AUTOSAR XML (schema 4-2-1)
package /VehicleProject
  system System
package /TP
  can tp config CAN00_CAN: communication-cluster=CAN00, can-tp-ecu{cycle-time-main-function=0.005, ecu-instance=MyECU}
    can tp channel TPCH: channel-id=0, channel-mode=FULL-DUPLEX-MODE
    tp-connections:
      addressing-format=STANDARD, can-tp-channel=TPCH, data-pdu=msg_diag_RequestGlobal_Tp_oCAN00, receiver=TN_MyECU, ta-type=FUNCTIONAL, tp-sdu=msg_diag_RequestGlobal_oCAN00, transmitter=TN_Tester
      addressing-format=STANDARD, can-tp-channel=TPCH, data-pdu=msg_diag_Response_MyECU_Tp_oCAN00, flow-control-pdu=msg_diag_Request_MyECU_Tp_oCAN00, receiver=TN_Tester, ta-type=PHYSICAL, tp-sdu=msg_diag_Response_MyECU_oCAN00, transmitter=TN_MyECU
      addressing-format=STANDARD, can-tp-channel=TPCH, data-pdu=msg_diag_Request_MyECU_Tp_oCAN00, flow-control-pdu=msg_diag_Response_MyECU_Tp_oCAN00, receiver=TN_MyECU, ta-type=PHYSICAL, tp-sdu=msg_diag_Request_MyECU_oCAN00, transmitter=TN_Tester
    can tp node TN_MyECU: connector=CN_CAN00
    can tp node TN_Tester
package /Cluster
  can cluster CAN00: protocol-name=CAN
    can physical channel CHNL: comm-connectors=CN_CAN00
      frame msg_diag_Request_MyECU_oCAN00: id 0x610, to MyECU, frame-length=8, can-addressing-mode=STANDARD
        n pdu msg_diag_Request_MyECU_Tp_oCAN00: length=8
      frame msg_diag_RequestGlobal_oCAN00: id 0x614, to MyECU, frame-length=8, can-addressing-mode=STANDARD
        n pdu msg_diag_RequestGlobal_Tp_oCAN00: length=8
      frame msg_diag_Response_MyECU_oCAN00: id 0x612, from MyECU, frame-length=8, can-addressing-mode=STANDARD
        n pdu msg_diag_Response_MyECU_Tp_oCAN00: length=8
      frame msg_nm_MyECU_oCAN00: id 0x400, from MyECU, frame-length=8, can-addressing-mode=STANDARD
        nm pdu msg_nm_MyECU_oCAN00: length=8, unused-bit-pattern=0
      frame msg_nm_RearECU_oCAN00: id 0x401, to MyECU, frame-length=8, can-addressing-mode=STANDARD
        nm pdu msg_nm_RearECU_oCAN00: length=8, unused-bit-pattern=0
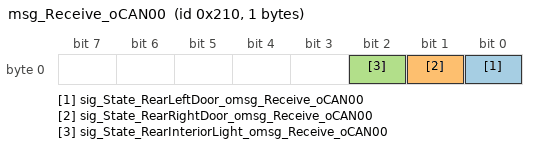
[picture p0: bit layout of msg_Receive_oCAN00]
      frame msg_Receive_oCAN00: id 0x210, to MyECU, frame-length=1, can-addressing-mode=STANDARD
        pdu msg_Receive_oCAN00: length=1, minimum-delay=0, transmission-mode-false-timing=cyclic-timing={time-offset=0, time-period=0.1}, transmission-mode-true-timing=cyclic-timing={time-offset=0, time-period=0.1}, unused-bit-pattern=0
          signal sig_State_RearLeftDoor_omsg_Receive_oCAN00: start 0, 1 bit, little-endian, init-value=0, base-type=boolean, compu-method=CM_sig_State_RearLeftDoor, transfer-property=PENDING, to MyECU
          signal sig_State_RearRightDoor_omsg_Receive_oCAN00: start 1, 1 bit, little-endian, init-value=0, base-type=boolean, compu-method=CM_sig_State_RearRightDoor, transfer-property=PENDING, to MyECU
          signal sig_State_RearInteriorLight_omsg_Receive_oCAN00: start 2, 1 bit, little-endian, init-value=0, base-type=boolean, compu-method=CM_sig_State_RearInteriorLight, transfer-property=PENDING, to MyECU
      frame msg_Transmit_oCAN00: id 0x200, from MyECU, frame-length=1, can-addressing-mode=STANDARD
        pdu msg_Transmit_oCAN00: length=1, minimum-delay=0, transmission-mode-false-timing=cyclic-timing={time-offset=0, time-period=0.1}, transmission-mode-true-timing=cyclic-timing={time-offset=0, time-period=0.1}, unused-bit-pattern=0
          signal sig_RearInteriorLight_omsg_Transmit_oCAN00: start 0, 1 bit, little-endian, init-value=0, base-type=boolean, compu-method=CM_sig_RearInteriorLight, transfer-property=PENDING
      pdu triggering PT_msg_diag_Request_MyECU: pdu=msg_diag_Request_MyECU_oCAN00, to MyECU
      pdu triggering PT_msg_diag_RequestGlobal: pdu=msg_diag_RequestGlobal_oCAN00, to MyECU
      pdu triggering PT_msg_diag_Response_MyECU: pdu=msg_diag_Response_MyECU_oCAN00, from MyECU
package /ECU
  ecu instance MyECU: associated-com-i-pdu-group=[MyECU_oCAN00_Rx, MyECU_oCAN00_Tx]
    can communication controller CT_CAN00
    can communication connector CN_CAN00: comm-controller=CT_CAN00
package /IPDUGroup
  i signal i pdu group MyECU_oCAN00_Rx: communication-direction=IN, i-signal-i-pdus=msg_Receive_oCAN00
  i signal i pdu group MyECU_oCAN00_Tx: communication-direction=OUT, i-signal-i-pdus=msg_Transmit_oCAN00
package /PDU
  dcm i pdu msg_diag_Request_MyECU_oCAN00: length=8, diag-pdu-type=DIAG-REQUEST
  dcm i pdu msg_diag_RequestGlobal_oCAN00: length=7, diag-pdu-type=DIAG-REQUEST
  dcm i pdu msg_diag_Response_MyECU_oCAN00: length=8, diag-pdu-type=DIAG-RESPONSE
